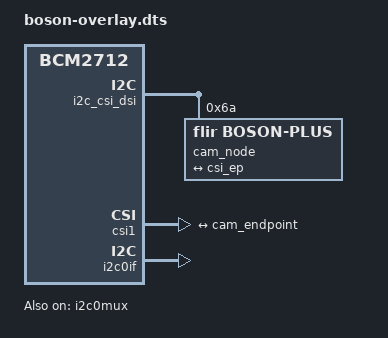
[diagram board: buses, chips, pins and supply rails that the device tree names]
// SPDX-License-Identifier: GPL-2.0-only
// FLIR Boson+ MIPI thermal camera through the ARK Boson Adapter.
//
// The Boson runs from the connector's 3.3 V and its own oscillator, and the
// adapter wires no reset or clock to it, so the node has no clock or supply.
// The adapter routes the Boson's EXT_SYNC to the connector's pin 18 through
// R12. On the Just A Pi's CAM1 (the cam0 parameter) that is the CM5's
// CAM_GPIO1 (GPIO35), which nothing on the Pi drives, so it can be read as a
// GPIO input; CAM2 has no pin 18.
/dts-v1/;
/plugin/;

/{
	compatible = "brcm,bcm2712";

	i2c_frag: fragment@0 {
		target = <&i2c_csi_dsi>;
		__overlay__ {
			#address-cells = <1>;
			#size-cells = <0>;
			status = "okay";

			cam_node: boson@6a {
				compatible = "flir,boson-plus";
				reg = <0x6a>;
				status = "okay";

				rotation = <0>;
				orientation = <2>;

				port {
					cam_endpoint: endpoint {
						bus-type = <4>;
						clock-lanes = <0>;
						data-lanes = <1 2>;
						link-frequencies =
							/bits/ 64 <246000000>;
						remote-endpoint = <&csi_ep>;
					};
				};
			};
		};
	};

	csi_frag: fragment@1 {
		target = <&csi1>;
		csi: __overlay__ {
			status = "okay";

			port {
				csi_ep: endpoint {
					remote-endpoint = <&cam_endpoint>;
					clock-lanes = <0>;
					data-lanes = <1 2>;
				};
			};
		};
	};

	fragment@2 {
		target = <&i2c0if>;
		__overlay__ {
			status = "okay";
		};
	};

	fragment@3 {
		target = <&i2c0mux>;
		__overlay__ {
			status = "okay";
		};
	};

	__overrides__ {
		rotation = <&cam_node>,"rotation:0";
		orientation = <&cam_node>,"orientation:0";
		cam0 = <&i2c_frag>, "target:0=",<&i2c_csi_dsi0>,
		       <&csi_frag>, "target:0=",<&csi0>;
	};
};
